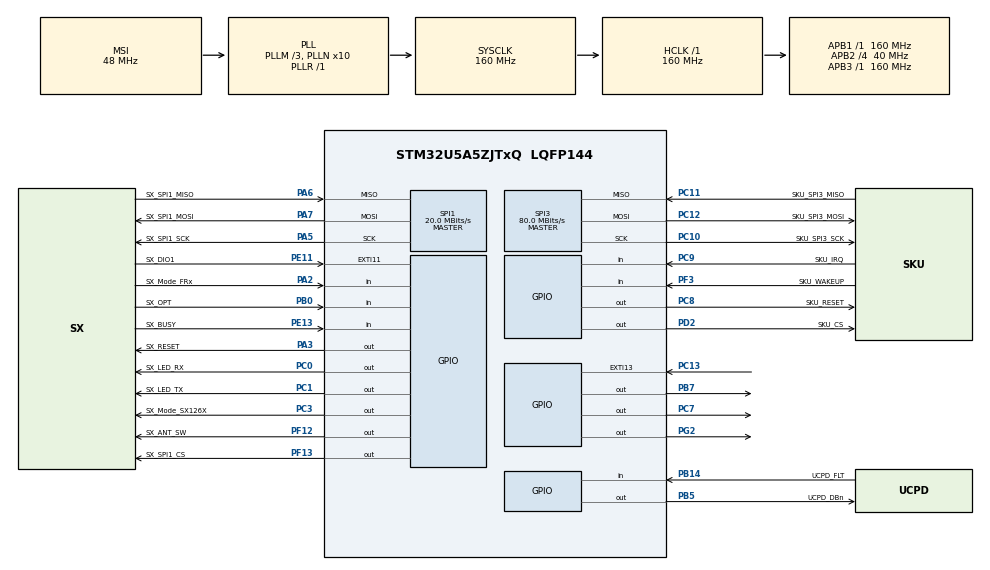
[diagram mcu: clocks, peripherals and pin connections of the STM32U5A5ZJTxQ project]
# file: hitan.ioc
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CORTEX_M33_NS.userName=CORTEX_M33
Mcu.Family=STM32U5
Mcu.Name=STM32U5A5ZJTxQ
Mcu.Package=LQFP144
NUCLEO-U5A5ZJ-Q.BUTTON=1
NUCLEO-U5A5ZJ-Q.LD1=true
NUCLEO-U5A5ZJ-Q.LD2=true
NUCLEO-U5A5ZJ-Q.LD3=true
NUCLEO-U5A5ZJ-Q.VCP=true
NVIC.EXTI11_IRQn=true\:0\:0\:false\:false\:true\:true\:true\:true
NVIC.EXTI13_IRQn=true\:0\:0\:false\:false\:true\:false\:true\:true
NVIC.PriorityGroup=NVIC_PRIORITYGROUP_4
PA10.Signal=USART1_RX
PA11.Signal=USB_OTG_HS_DM
PA12.Signal=USB_OTG_HS_DP
PA13\ (JTMS/SWDIO).Mode=Trace_Asynchronous_SW
PA13\ (JTMS/SWDIO).Signal=DEBUG_JTMS-SWDIO
PA14\ (JTCK/SWCLK).Mode=Trace_Asynchronous_SW
PA14\ (JTCK/SWCLK).Signal=DEBUG_JTCK-SWCLK
PA15\ (JTDI).Signal=UCPD1_CC1
PA2.GPIO_Label=SX_Mode_FRx
PA2.Signal=GPIO_Input
PA3.GPIO_Label=SX_RESET
PA3.Signal=GPIO_Output
PA5.GPIO_Label=SX_SPI1_SCK
PA5.Mode=Full_Duplex_Master
PA5.Signal=SPI1_SCK
PA6.GPIO_Label=SX_SPI1_MISO
PA6.Mode=Full_Duplex_Master
PA6.Signal=SPI1_MISO
PA7.GPIO_Label=SX_SPI1_MOSI
PA7.Mode=Full_Duplex_Master
PA7.Signal=SPI1_MOSI
PA9.Signal=USART1_TX
PB0.GPIO_Label=SX_OPT
PB0.Signal=GPIO_Input
PB14.GPIO_Label=UCPD_FLT
PB14.Signal=GPIO_Input
PB15.Signal=UCPD1_CC2
PB3\ (JTDO/TRACESWO).Mode=Trace_Asynchronous_SW
PB3\ (JTDO/TRACESWO).Signal=DEBUG_JTDO-SWO
PB5.GPIO_Label=UCPD_DBn
PB5.Signal=GPIO_Output
PB7.Signal=GPIO_Output
PC0.GPIO_Label=SX_LED_RX
PC0.Signal=GPIO_Output
PC1.GPIO_Label=SX_LED_TX
PC1.Signal=GPIO_Output
PC10.GPIO_Label=SKU_SPI3_SCK
PC10.Mode=Full_Duplex_Master
PC10.Signal=SPI3_SCK
PC11.GPIO_Label=SKU_SPI3_MISO
PC11.Mode=Full_Duplex_Master
PC11.Signal=SPI3_MISO
PC12.GPIO_Label=SKU_SPI3_MOSI
PC12.Mode=Full_Duplex_Master
PC12.Signal=SPI3_MOSI
PC13.Signal=GPXTI13
PC14-OSC32_IN\ (PC14).Mode=LSE-External-Oscillator
PC14-OSC32_IN\ (PC14).Signal=RCC_OSC32_IN
PC15-OSC32_OUT\ (PC15).Mode=LSE-External-Oscillator
PC15-OSC32_OUT\ (PC15).Signal=RCC_OSC32_OUT
PC2.GPIO_Label=VBUS_SENSE
PC2.Signal=ADC1_IN3
PC3.GPIO_Label=SX_Mode_SX126X
PC3.Signal=GPIO_Output
PC7.Signal=GPIO_Output
PC8.GPIO_Label=SKU_RESET
PC8.Signal=GPIO_Output
PC9.GPIO_Label=SKU_IRQ
PC9.Signal=GPIO_Input
PD2.GPIO_Label=SKU_CS
PD2.Signal=GPIO_Output
PE11.GPIO_Label=SX_DIO1
PE11.GPIO_ModeDefaultEXTI=GPIO_MODE_IT_RISING
PE11.GPIO_PuPd=GPIO_NOPULL
PE11.Privilege=EXTI_LINE_NPRIV
PE11.Signal=GPXTI11
PE13.GPIO_Label=SX_BUSY
PE13.Signal=GPIO_Input
PF12.GPIO_Label=SX_ANT_SW
PF12.Signal=GPIO_Output
PF13.GPIO_Label=SX_SPI1_CS
PF13.Signal=GPIO_Output
PF3.GPIO_Label=SKU_WAKEUP
PF3.Signal=GPIO_Input
PG2.Signal=GPIO_Output
PH0-OSC_IN\ (PH0).Mode=HSE-External-Oscillator
PH0-OSC_IN\ (PH0).Signal=RCC_OSC_IN
PH1-OSC_OUT\ (PH1).Mode=HSE-External-Oscillator
PH1-OSC_OUT\ (PH1).Signal=RCC_OSC_OUT
PWR.PowerMode=PWR_SMPS_SUPPLY
ProjectManager.HeapSize=0x200
ProjectManager.StackSize=0x400
ProjectManager.TargetToolchain=STM32CubeIDE
RCC.ADCFreq_Value=16000000
RCC.AHBFreq_Value=160000000
RCC.APB1Freq_Value=160000000
RCC.APB1TimFreq_Value=160000000
RCC.APB2CLKDivider=RCC_HCLK_DIV4
RCC.APB2Freq_Value=40000000
RCC.APB2TimFreq_Value=80000000
RCC.APB3Freq_Value=160000000
RCC.CortexFreq_Value=160000000
RCC.DACCLockSelectionVirtual=RCC_DAC1CLKSOURCE_LSI
RCC.EPOD_VALUE=48000000
RCC.HCLKFreq_Value=160000000
RCC.HSE_VALUE=8000000
RCC.HSI48_VALUE=48000000
RCC.HSI_VALUE=16000000
RCC.LSIDIV_VALUE=32000
RCC.MSIClockRange=RCC_MSIRANGE_0
RCC.MSI_VALUE=48000000
RCC.PLL1P=8
RCC.PLL1R=1
RCC.PLL2FRACN=0
RCC.PLL3FRACN=0
RCC.PLLFRACN=0
RCC.PLLM=3
RCC.PLLN=10
RCC.SPI1CLockSelection=RCC_SPI1CLKSOURCE_PCLK2
RCC.SYSCLKFreq_VALUE=160000000
RCC.SYSCLKSource=RCC_SYSCLKSOURCE_PLLCLK
RCC.VCOOutputFreq_Value=160000000
SPI1.BaudRatePrescaler=SPI_BAUDRATEPRESCALER_2
SPI1.CalculateBaudRate=20.0 MBits/s
SPI1.DataSize=SPI_DATASIZE_8BIT
SPI1.Direction=SPI_DIRECTION_2LINES
SPI1.Mode=SPI_MODE_MASTER
SPI1.VirtualType=VM_MASTER
SPI3.CalculateBaudRate=80.0 MBits/s
SPI3.Direction=SPI_DIRECTION_2LINES
SPI3.Mode=SPI_MODE_MASTER
SPI3.VirtualType=VM_MASTER
VP_ICACHE_VS_ICACHE.Mode=DirectMappedCache
VP_LPBAMQUEUE_VS_QUEUE.Mode=QUEUEMODE
VP_LPBAM_VS_SIG1.Mode=SmartRun
VP_LPBAM_VS_SIG4.Mode=LPDMA1
VP_MEMORYMAP_VS_MEMORYMAP.Mode=CurAppReg
VP_NUCLEO-U5A5ZJ-Q_VS_BSP_COMMON.Mode=COMMON
VP_PWR_VS_DBSignals.Mode=DisableDeadBatterySignals
VP_PWR_VS_LPOM.Mode=PowerOptimisation
VP_PWR_VS_SECSignals.Mode=Security/Privilege
VP_TIM2_VS_ClockSourceINT.Mode=Internal
board=NUCLEO-U5A5ZJ-Q

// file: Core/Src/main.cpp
/* USER CODE BEGIN Header */
/**
  ******************************************************************************
  * @file           : main.c
  * @brief          : Main program body
  ******************************************************************************
  * @attention
  *
  * Copyright (c) 2025 STMicroelectronics.
  * All rights reserved.
  *
  * This software is licensed under terms that can be found in the LICENSE file
  * in the root directory of this software component.
  * If no LICENSE file comes with this software, it is provided AS-IS.
  *
  ******************************************************************************
  */
/* USER CODE END Header */
#include "main.h"
/* USER CODE BEGIN Includes */
#include "dw1000.h"

#include "../Lora/Inc/Lora.h"
/* USER CODE END Includes */

COM_InitTypeDef BspCOMInit;

SPI_HandleTypeDef hspi1;
SPI_HandleTypeDef hspi3;

TIM_HandleTypeDef htim2;

void SystemClock_Config(void);
static void SystemPower_Config(void);
static void MX_GPIO_Init(void);
static void MX_ICACHE_Init(void);
static void MX_SPI1_Init(void);
static void MX_TIM2_Init(void);
static void MX_SPI3_Init(void);

/* USER CODE BEGIN 0 */

LoraRxInfo_t rxInfo;
/* USER CODE END 0 */

int main(void)
{

  /* MCU Configuration--------------------------------------------------------*/

  /* Reset of all peripherals, Initializes the Flash interface and the Systick. */
  HAL_Init();

  /* Configure the system clock */
  SystemClock_Config();

  /* Configure the System Power */
  SystemPower_Config();

  /* Initialize all configured peripherals */
  MX_GPIO_Init();
  MX_ICACHE_Init();
  MX_SPI1_Init();
  MX_TIM2_Init();
  MX_SPI3_Init();

  /* Initialize leds */
  BSP_LED_Init(LED_GREEN);
  BSP_LED_Init(LED_BLUE);
  BSP_LED_Init(LED_RED);

  /* Initialize USER push-button, will be used to trigger an interrupt each time it's pressed.*/
  BSP_PB_Init(BUTTON_USER, BUTTON_MODE_EXTI);

  /* Initialize COM1 port (115200, 8 bits (7-bit data + 1 stop bit), no parity */
  BspCOMInit.BaudRate   = 115200;
  BspCOMInit.WordLength = COM_WORDLENGTH_8B;
  BspCOMInit.StopBits   = COM_STOPBITS_1;
  BspCOMInit.Parity     = COM_PARITY_NONE;
  BspCOMInit.HwFlowCtl  = COM_HWCONTROL_NONE;
  if (BSP_COM_Init(COM1, &BspCOMInit) != BSP_ERROR_NONE)
  {
    Error_Handler();
  }

  /* Infinite loop */
  /* USER CODE BEGIN WHILE */

  printf("\n\n\n");
  printf("----------------------\r\n");
  printf("	Version code: %s \r\n", VERSION);
  printf("----------------------\r\n");
  printf("\n\n\n");
//  	  Lora_Operation_TX();

//  	  Lora_Operation_RX();

  	  if(!dwmInit()) {// init failed
  		  printf("Init Failed\r\n");
  		  while (1);
  	   }
  	   else{
  		  printf("Init DW1000 Succeed\r\n");
  	  }

  	  dwConfig(&config);
  	  Lora_init();
  	  //dw_main();

  	  while (1)
  	  {
  	//	  Lora_Receive();
  		  dwRange();
  		  RunRXStateMachine();
  	  }
  /* USER CODE END 3 */
}

void SystemClock_Config(void)
{
  RCC_OscInitTypeDef RCC_OscInitStruct = {0};
  RCC_ClkInitTypeDef RCC_ClkInitStruct = {0};

  /** Configure the main internal regulator output voltage
  */
  if (HAL_PWREx_ControlVoltageScaling(PWR_REGULATOR_VOLTAGE_SCALE1) != HAL_OK)
  {
    Error_Handler();
  }

  /** Initializes the CPU, AHB and APB buses clocks
  */
  RCC_OscInitStruct.OscillatorType = RCC_OSCILLATORTYPE_MSI;
  RCC_OscInitStruct.MSIState = RCC_MSI_ON;
  RCC_OscInitStruct.MSICalibrationValue = RCC_MSICALIBRATION_DEFAULT;
  RCC_OscInitStruct.MSIClockRange = RCC_MSIRANGE_0;
  RCC_OscInitStruct.PLL.PLLState = RCC_PLL_ON;
  RCC_OscInitStruct.PLL.PLLSource = RCC_PLLSOURCE_MSI;
  RCC_OscInitStruct.PLL.PLLMBOOST = RCC_PLLMBOOST_DIV4;
  RCC_OscInitStruct.PLL.PLLM = 3;
  RCC_OscInitStruct.PLL.PLLN = 10;
  RCC_OscInitStruct.PLL.PLLP = 8;
  RCC_OscInitStruct.PLL.PLLQ = 2;
  RCC_OscInitStruct.PLL.PLLR = 1;
  RCC_OscInitStruct.PLL.PLLRGE = RCC_PLLVCIRANGE_1;
  RCC_OscInitStruct.PLL.PLLFRACN = 0;
  if (HAL_RCC_OscConfig(&RCC_OscInitStruct) != HAL_OK)
  {
    Error_Handler();
  }

  /** Initializes the CPU, AHB and APB buses clocks
  */
  RCC_ClkInitStruct.ClockType = RCC_CLOCKTYPE_HCLK|RCC_CLOCKTYPE_SYSCLK
                              |RCC_CLOCKTYPE_PCLK1|RCC_CLOCKTYPE_PCLK2
                              |RCC_CLOCKTYPE_PCLK3;
  RCC_ClkInitStruct.SYSCLKSource = RCC_SYSCLKSOURCE_PLLCLK;
  RCC_ClkInitStruct.AHBCLKDivider = RCC_SYSCLK_DIV1;
  RCC_ClkInitStruct.APB1CLKDivider = RCC_HCLK_DIV1;
  RCC_ClkInitStruct.APB2CLKDivider = RCC_HCLK_DIV4;
  RCC_ClkInitStruct.APB3CLKDivider = RCC_HCLK_DIV1;

  if (HAL_RCC_ClockConfig(&RCC_ClkInitStruct, FLASH_LATENCY_4) != HAL_OK)
  {
    Error_Handler();
  }
}

/**
  * @brief Power Configuration
  * @retval None
  */
static void SystemPower_Config(void)
{

  /*
   * Disable the internal Pull-Up in Dead Battery pins of UCPD peripheral
   */
  HAL_PWREx_DisableUCPDDeadBattery();

  /*
   * Switch to SMPS regulator instead of LDO
   */
  if (HAL_PWREx_ConfigSupply(PWR_SMPS_SUPPLY) != HAL_OK)
  {
    Error_Handler();
  }
}

static void MX_ICACHE_Init(void)
{

  /** Enable instruction cache in 1-way (direct mapped cache)
  */
  if (HAL_ICACHE_ConfigAssociativityMode(ICACHE_1WAY) != HAL_OK)
  {
    Error_Handler();
  }
  if (HAL_ICACHE_Enable() != HAL_OK)
  {
    Error_Handler();
  }

}

static void MX_SPI1_Init(void)
{

  SPI_AutonomousModeConfTypeDef HAL_SPI_AutonomousMode_Cfg_Struct = {0};

  /* SPI1 parameter configuration*/
  hspi1.Instance = SPI1;
  hspi1.Init.Mode = SPI_MODE_MASTER;
  hspi1.Init.Direction = SPI_DIRECTION_2LINES;
  hspi1.Init.DataSize = SPI_DATASIZE_8BIT;
  hspi1.Init.CLKPolarity = SPI_POLARITY_LOW;
  hspi1.Init.CLKPhase = SPI_PHASE_1EDGE;
  hspi1.Init.NSS = SPI_NSS_SOFT;
  hspi1.Init.BaudRatePrescaler = SPI_BAUDRATEPRESCALER_2;
  hspi1.Init.FirstBit = SPI_FIRSTBIT_MSB;
  hspi1.Init.TIMode = SPI_TIMODE_DISABLE;
  hspi1.Init.CRCCalculation = SPI_CRCCALCULATION_DISABLE;
  hspi1.Init.CRCPolynomial = 0x7;
  hspi1.Init.NSSPMode = SPI_NSS_PULSE_ENABLE;
  hspi1.Init.NSSPolarity = SPI_NSS_POLARITY_LOW;
  hspi1.Init.FifoThreshold = SPI_FIFO_THRESHOLD_01DATA;
  hspi1.Init.MasterSSIdleness = SPI_MASTER_SS_IDLENESS_00CYCLE;
  hspi1.Init.MasterInterDataIdleness = SPI_MASTER_INTERDATA_IDLENESS_00CYCLE;
  hspi1.Init.MasterReceiverAutoSusp = SPI_MASTER_RX_AUTOSUSP_DISABLE;
  hspi1.Init.MasterKeepIOState = SPI_MASTER_KEEP_IO_STATE_DISABLE;
  hspi1.Init.IOSwap = SPI_IO_SWAP_DISABLE;
  hspi1.Init.ReadyMasterManagement = SPI_RDY_MASTER_MANAGEMENT_INTERNALLY;
  hspi1.Init.ReadyPolarity = SPI_RDY_POLARITY_HIGH;
  if (HAL_SPI_Init(&hspi1) != HAL_OK)
  {
    Error_Handler();
  }
  HAL_SPI_AutonomousMode_Cfg_Struct.TriggerState = SPI_AUTO_MODE_DISABLE;
  HAL_SPI_AutonomousMode_Cfg_Struct.TriggerSelection = SPI_GRP1_GPDMA_CH0_TCF_TRG;
  HAL_SPI_AutonomousMode_Cfg_Struct.TriggerPolarity = SPI_TRIG_POLARITY_RISING;
  if (HAL_SPIEx_SetConfigAutonomousMode(&hspi1, &HAL_SPI_AutonomousMode_Cfg_Struct) != HAL_OK)
  {
    Error_Handler();
  }

}
static void MX_SPI3_Init(void)
{

  SPI_AutonomousModeConfTypeDef HAL_SPI_AutonomousMode_Cfg_Struct = {0};

  /* SPI3 parameter configuration*/
  hspi3.Instance = SPI3;
  hspi3.Init.Mode = SPI_MODE_MASTER;
  hspi3.Init.Direction = SPI_DIRECTION_2LINES;
  hspi3.Init.DataSize = SPI_DATASIZE_8BIT;
  hspi3.Init.CLKPolarity = SPI_POLARITY_LOW;
  hspi3.Init.CLKPhase = SPI_PHASE_1EDGE;
  hspi3.Init.NSS = SPI_NSS_SOFT;
  hspi3.Init.BaudRatePrescaler = SPI_BAUDRATEPRESCALER_2;
  hspi3.Init.FirstBit = SPI_FIRSTBIT_MSB;
  hspi3.Init.TIMode = SPI_TIMODE_DISABLE;
  hspi3.Init.CRCCalculation = SPI_CRCCALCULATION_DISABLE;
  hspi3.Init.CRCPolynomial = 0x7;
  hspi3.Init.NSSPMode = SPI_NSS_PULSE_ENABLE;
  hspi3.Init.NSSPolarity = SPI_NSS_POLARITY_LOW;
  hspi3.Init.FifoThreshold = SPI_FIFO_THRESHOLD_01DATA;
  hspi3.Init.MasterSSIdleness = SPI_MASTER_SS_IDLENESS_00CYCLE;
  hspi3.Init.MasterInterDataIdleness = SPI_MASTER_INTERDATA_IDLENESS_00CYCLE;
  hspi3.Init.MasterReceiverAutoSusp = SPI_MASTER_RX_AUTOSUSP_DISABLE;
  hspi3.Init.MasterKeepIOState = SPI_MASTER_KEEP_IO_STATE_DISABLE;
  hspi3.Init.IOSwap = SPI_IO_SWAP_DISABLE;
  hspi3.Init.ReadyMasterManagement = SPI_RDY_MASTER_MANAGEMENT_INTERNALLY;
  hspi3.Init.ReadyPolarity = SPI_RDY_POLARITY_HIGH;
  if (HAL_SPI_Init(&hspi3) != HAL_OK)
  {
    Error_Handler();
  }
  HAL_SPI_AutonomousMode_Cfg_Struct.TriggerState = SPI_AUTO_MODE_DISABLE;
  HAL_SPI_AutonomousMode_Cfg_Struct.TriggerSelection = SPI_GRP2_LPDMA_CH0_TCF_TRG;
  HAL_SPI_AutonomousMode_Cfg_Struct.TriggerPolarity = SPI_TRIG_POLARITY_RISING;
  if (HAL_SPIEx_SetConfigAutonomousMode(&hspi3, &HAL_SPI_AutonomousMode_Cfg_Struct) != HAL_OK)
  {
    Error_Handler();
  }

}

static void MX_TIM2_Init(void)
{

  TIM_ClockConfigTypeDef sClockSourceConfig = {0};
  TIM_MasterConfigTypeDef sMasterConfig = {0};

  htim2.Instance = TIM2;
  htim2.Init.Prescaler = 0;
  htim2.Init.CounterMode = TIM_COUNTERMODE_UP;
  htim2.Init.Period = 4294967295;
  htim2.Init.ClockDivision = TIM_CLOCKDIVISION_DIV1;
  htim2.Init.AutoReloadPreload = TIM_AUTORELOAD_PRELOAD_DISABLE;
  if (HAL_TIM_Base_Init(&htim2) != HAL_OK)
  {
    Error_Handler();
  }
  sClockSourceConfig.ClockSource = TIM_CLOCKSOURCE_INTERNAL;
  if (HAL_TIM_ConfigClockSource(&htim2, &sClockSourceConfig) != HAL_OK)
  {
    Error_Handler();
  }
  sMasterConfig.MasterOutputTrigger = TIM_TRGO_RESET;
  sMasterConfig.MasterSlaveMode = TIM_MASTERSLAVEMODE_DISABLE;
  if (HAL_TIMEx_MasterConfigSynchronization(&htim2, &sMasterConfig) != HAL_OK)
  {
    Error_Handler();
  }

}

static void MX_GPIO_Init(void)
{
  GPIO_InitTypeDef GPIO_InitStruct = {0};

  /* GPIO Ports Clock Enable */
  __HAL_RCC_GPIOC_CLK_ENABLE();
  __HAL_RCC_GPIOF_CLK_ENABLE();
  __HAL_RCC_GPIOH_CLK_ENABLE();
  __HAL_RCC_GPIOA_CLK_ENABLE();
  __HAL_RCC_GPIOB_CLK_ENABLE();
  __HAL_RCC_GPIOE_CLK_ENABLE();
  __HAL_RCC_GPIOD_CLK_ENABLE();

  /*Configure GPIO pin Output Level */
  HAL_GPIO_WritePin(GPIOC, SX_LED_RX_Pin|SX_LED_TX_Pin|SX_Mode_SX126X_Pin|SKU_RESET_Pin, GPIO_PIN_RESET);

  /*Configure GPIO pin Output Level */
  HAL_GPIO_WritePin(SX_RESET_GPIO_Port, SX_RESET_Pin, GPIO_PIN_RESET);

  /*Configure GPIO pin Output Level */
  HAL_GPIO_WritePin(GPIOF, SX_ANT_SW_Pin|SX_SPI1_CS_Pin, GPIO_PIN_RESET);

  /*Configure GPIO pin Output Level */
 HAL_GPIO_WritePin(SKU_CS_GPIO_Port, SKU_CS_Pin, GPIO_PIN_RESET);

  /*Configure GPIO pin Output Level */
  HAL_GPIO_WritePin(UCPD_DBn_GPIO_Port, UCPD_DBn_Pin, GPIO_PIN_RESET);

  /*Configure GPIO pin : SKU_WAKEUP_Pin */
  GPIO_InitStruct.Pin = SKU_WAKEUP_Pin;
  GPIO_InitStruct.Mode = GPIO_MODE_INPUT;
  GPIO_InitStruct.Pull = GPIO_NOPULL;
  HAL_GPIO_Init(SKU_WAKEUP_GPIO_Port, &GPIO_InitStruct);

  /*Configure GPIO pins : SX_LED_RX_Pin SX_LED_TX_Pin SX_Mode_SX126X_Pin SKU_RESET_Pin */
  GPIO_InitStruct.Pin = SX_LED_RX_Pin|SX_LED_TX_Pin|SX_Mode_SX126X_Pin|SKU_RESET_Pin;
  GPIO_InitStruct.Mode = GPIO_MODE_OUTPUT_PP;
  GPIO_InitStruct.Pull = GPIO_NOPULL;
  GPIO_InitStruct.Speed = GPIO_SPEED_FREQ_LOW;
  HAL_GPIO_Init(GPIOC, &GPIO_InitStruct);

  /*Configure GPIO pin : VBUS_SENSE_Pin */
  GPIO_InitStruct.Pin = VBUS_SENSE_Pin;
  GPIO_InitStruct.Mode = GPIO_MODE_ANALOG;
  GPIO_InitStruct.Pull = GPIO_NOPULL;
  HAL_GPIO_Init(VBUS_SENSE_GPIO_Port, &GPIO_InitStruct);

  /*Configure GPIO pin : SX_Mode_FRx_Pin */
  GPIO_InitStruct.Pin = SX_Mode_FRx_Pin;
  GPIO_InitStruct.Mode = GPIO_MODE_INPUT;
  GPIO_InitStruct.Pull = GPIO_NOPULL;
  HAL_GPIO_Init(SX_Mode_FRx_GPIO_Port, &GPIO_InitStruct);

  /*Configure GPIO pin : SX_RESET_Pin */
  GPIO_InitStruct.Pin = SX_RESET_Pin;
  GPIO_InitStruct.Mode = GPIO_MODE_OUTPUT_PP;
  GPIO_InitStruct.Pull = GPIO_NOPULL;
  GPIO_InitStruct.Speed = GPIO_SPEED_FREQ_LOW;
  HAL_GPIO_Init(SX_RESET_GPIO_Port, &GPIO_InitStruct);

  /*Configure GPIO pins : SX_OPT_Pin UCPD_FLT_Pin */
  GPIO_InitStruct.Pin = SX_OPT_Pin|UCPD_FLT_Pin;
  GPIO_InitStruct.Mode = GPIO_MODE_INPUT;
  GPIO_InitStruct.Pull = GPIO_NOPULL;
  HAL_GPIO_Init(GPIOB, &GPIO_InitStruct);

  /*Configure GPIO pins : SX_ANT_SW_Pin SX_SPI1_CS_Pin */
  GPIO_InitStruct.Pin = SX_ANT_SW_Pin|SX_SPI1_CS_Pin;
  GPIO_InitStruct.Mode = GPIO_MODE_OUTPUT_PP;
  GPIO_InitStruct.Pull = GPIO_NOPULL;
  GPIO_InitStruct.Speed = GPIO_SPEED_FREQ_LOW;
  HAL_GPIO_Init(GPIOF, &GPIO_InitStruct);

  /*Configure GPIO pin : SX_DIO1_Pin */
  GPIO_InitStruct.Pin = SX_DIO1_Pin;
  GPIO_InitStruct.Mode = GPIO_MODE_IT_RISING;
  GPIO_InitStruct.Pull = GPIO_NOPULL;
  HAL_GPIO_Init(SX_DIO1_GPIO_Port, &GPIO_InitStruct);

  /*Configure GPIO pin : SX_BUSY_Pin */
  GPIO_InitStruct.Pin = SX_BUSY_Pin;
  GPIO_InitStruct.Mode = GPIO_MODE_INPUT;
  GPIO_InitStruct.Pull = GPIO_NOPULL;
  HAL_GPIO_Init(SX_BUSY_GPIO_Port, &GPIO_InitStruct);

  /*Configure GPIO pin : PB15 */
  GPIO_InitStruct.Pin = GPIO_PIN_15;
  GPIO_InitStruct.Mode = GPIO_MODE_ANALOG;
  GPIO_InitStruct.Pull = GPIO_NOPULL;
  HAL_GPIO_Init(GPIOB, &GPIO_InitStruct);

  /*Configure GPIO pin : SKU_IRQ_Pin */
  GPIO_InitStruct.Pin = SKU_IRQ_Pin;
  GPIO_InitStruct.Mode = GPIO_MODE_INPUT;
  GPIO_InitStruct.Pull = GPIO_NOPULL;
  HAL_GPIO_Init(SKU_IRQ_GPIO_Port, &GPIO_InitStruct);

  /*Configure GPIO pins : PA11 PA12 */
  GPIO_InitStruct.Pin = GPIO_PIN_11|GPIO_PIN_12;
  GPIO_InitStruct.Mode = GPIO_MODE_AF_PP;
  GPIO_InitStruct.Pull = GPIO_NOPULL;
  GPIO_InitStruct.Speed = GPIO_SPEED_FREQ_LOW;
  HAL_GPIO_Init(GPIOA, &GPIO_InitStruct);

  /*Configure GPIO pin : PA15 */
  GPIO_InitStruct.Pin = GPIO_PIN_15;
  GPIO_InitStruct.Mode = GPIO_MODE_ANALOG;
  GPIO_InitStruct.Pull = GPIO_NOPULL;
  HAL_GPIO_Init(GPIOA, &GPIO_InitStruct);

  /*Configure GPIO pin : SKU_CS_Pin */
  GPIO_InitStruct.Pin = SKU_CS_Pin;
  GPIO_InitStruct.Mode = GPIO_MODE_OUTPUT_PP;
  GPIO_InitStruct.Pull = GPIO_NOPULL;
  GPIO_InitStruct.Speed = GPIO_SPEED_FREQ_LOW;
  HAL_GPIO_Init(SKU_CS_GPIO_Port, &GPIO_InitStruct);

  /*Configure GPIO pin : UCPD_DBn_Pin */
  GPIO_InitStruct.Pin = UCPD_DBn_Pin;
  GPIO_InitStruct.Mode = GPIO_MODE_OUTPUT_PP;
  GPIO_InitStruct.Pull = GPIO_NOPULL;
  GPIO_InitStruct.Speed = GPIO_SPEED_FREQ_LOW;
  HAL_GPIO_Init(UCPD_DBn_GPIO_Port, &GPIO_InitStruct);

  /* EXTI interrupt init*/
  HAL_NVIC_SetPriority(EXTI11_IRQn, 0, 0);
  HAL_NVIC_EnableIRQ(EXTI11_IRQn);

}

void Error_Handler(void)
{
  __disable_irq();
  while (1)
  {
  }
}
